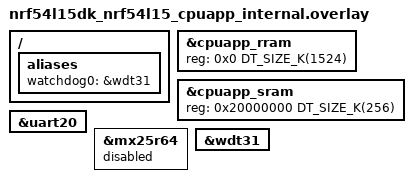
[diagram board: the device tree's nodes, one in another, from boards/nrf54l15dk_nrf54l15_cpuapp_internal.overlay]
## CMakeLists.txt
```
#
# Copyright (c) 2021 Nordic Semiconductor ASA
#
# SPDX-License-Identifier: LicenseRef-Nordic-5-Clause
#

cmake_minimum_required(VERSION 3.20.0)

find_package(Zephyr HINTS $ENV{ZEPHYR_BASE})

project(dummy)

# Enable GNU STD support and initialize the Matter Data Model.
include(${ZEPHYR_CONNECTEDHOMEIP_MODULE_DIR}/config/nrfconnect/app/enable-gnu-std.cmake)

# NORDIC SDK APP START
target_sources(app PRIVATE
    src/main.c
)

# NORDIC SDK APP END
```

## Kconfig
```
#
# Copyright (c) 2022 Nordic Semiconductor
#
# SPDX-License-Identifier: LicenseRef-Nordic-5-Clause
#
mainmenu "Matter dummy sample for DFU integration purpose"

config CHIP_DEVICE_VENDOR_ID
	int
	default 65521

config CHIP_DEVICE_PRODUCT_ID
	int
	default 32768

config UPDATEABLE_IMAGE_NUMBER
    int
    default 1

source "${ZEPHYR_CONNECTEDHOMEIP_MODULE_DIR}/config/nrfconnect/chip-module/Kconfig.features"
source "${ZEPHYR_CONNECTEDHOMEIP_MODULE_DIR}/config/nrfconnect/chip-module/Kconfig.defaults"
source "Kconfig.zephyr"
```

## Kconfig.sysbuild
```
#
# Copyright (c) 2023 Nordic Semiconductor ASA
#
# SPDX-License-Identifier: LicenseRef-Nordic-5-Clause
#

# Choose empty network core
config NRF_DEFAULT_EMPTY
	default y

#### Bootloader
choice BOOTLOADER
	default BOOTLOADER_MCUBOOT if !BOARD_NRF21540DK
endchoice

if BOOTLOADER_MCUBOOT

#### DFU multi-image support
config DFU_MULTI_IMAGE_PACKAGE_BUILD
	default y

config DFU_MULTI_IMAGE_PACKAGE_APP
	default y

config PM_EXTERNAL_FLASH_MCUBOOT_SECONDARY
	default y

#### DFU network core configuration
if SOC_SERIES_NRF53X

config MCUBOOT_UPDATEABLE_IMAGES
	default 2

choice MCUBOOT_MODE
	default MCUBOOT_MODE_OVERWRITE_ONLY
endchoice

choice BOOT_SIGNATURE_TYPE
	default BOOT_SIGNATURE_TYPE_RSA
endchoice

config SECURE_BOOT_NETCORE
	default y

config NETCORE_APP_UPDATE
	default y

config DFU_MULTI_IMAGE_PACKAGE_NET
	default y

endif # SOC_SERIES_NRF53X

if BOARD_NRF54L15DK || BOARD_NRF54LM20DK

# Disable checking the external drivers for nRF54L15 and nRF54LM20 DKs.
config PM_OVERRIDE_EXTERNAL_DRIVER_CHECK
	default y

endif # BOARD_NRF54L15DK || BOARD_NRF54LM20DK

endif # BOOTLOADER_MCUBOOT

config MATTER_OTA
	default y

config MATTER_OTA_IMAGE_FILE_NAME
	string
	default "matter.ota"

# Store the Wi-Fi firmware patch on external flash by default
if WIFI_NRF70

choice WIFI_PATCHES_EXT_FLASH_SUPPORT
	default WIFI_PATCHES_EXT_FLASH_STORE

endchoice

config DFU_MULTI_IMAGE_PACKAGE_WIFI_FW_PATCH
	default y

endif # WIFI_NRF70

source "${ZEPHYR_BASE}/share/sysbuild/Kconfig"
```

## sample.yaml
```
sample:
  description: Matter Dummy Sample
  name: Matter Dummy
tests:
  sample.matter.dummy:
    sysbuild: true
    build_only: true
    integration_platforms:
      - nrf52840dk/nrf52840
      - nrf5340dk/nrf5340/cpuapp
      - nrf7002dk/nrf5340/cpuapp
      - nrf54l15dk/nrf54l15/cpuapp
      - nrf54l15dk/nrf54l15/cpuapp/ns
      - nrf54lm20dk/nrf54lm20a/cpuapp
    platform_allow:
      - nrf52840dk/nrf52840
      - nrf5340dk/nrf5340/cpuapp
      - nrf7002dk/nrf5340/cpuapp
      - nrf54l15dk/nrf54l15/cpuapp
      - nrf54l15dk/nrf54l15/cpuapp/ns
      - nrf54lm20dk/nrf54lm20a/cpuapp
    tags: sysbuild ci_samples_matter
  sample.matter.dummy.internal:
    sysbuild: true
    build_only: true
    integration_platforms:
      - nrf54l15dk/nrf54l15/cpuapp
      - nrf54lm20dk/nrf54lm20a/cpuapp
    platform_allow:
      - nrf54l15dk/nrf54l15/cpuapp
      - nrf54lm20dk/nrf54lm20a/cpuapp
    extra_args:
      - FILE_SUFFIX=internal
    tags: sysbuild ci_samples_matter
```

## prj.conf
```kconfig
#
# Copyright (c) 2022 Nordic Semiconductor ASA
#
# SPDX-License-Identifier: LicenseRef-Nordic-5-Clause
#

CONFIG_PRINTK=y

CONFIG_BOOTLOADER_MCUBOOT=y
CONFIG_IMG_MANAGER=y
CONFIG_STREAM_FLASH=y
CONFIG_STREAM_FLASH_ERASE=y
CONFIG_FLASH=y
CONFIG_FLASH_MAP=y
CONFIG_MCUBOOT_IMG_MANAGER=y
CONFIG_NEWLIB_LIBC=y
```

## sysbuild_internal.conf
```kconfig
#
# Copyright (c) 2024 Nordic Semiconductor
#
# SPDX-License-Identifier: LicenseRef-Nordic-5-Clause
#

SB_CONFIG_PM_OVERRIDE_EXTERNAL_DRIVER_CHECK=n
SB_CONFIG_PM_EXTERNAL_FLASH_MCUBOOT_SECONDARY=n

# Enable the DFU image compression.
SB_CONFIG_MCUBOOT_MODE_OVERWRITE_ONLY=y
SB_CONFIG_MCUBOOT_COMPRESSED_IMAGE_SUPPORT=y
```

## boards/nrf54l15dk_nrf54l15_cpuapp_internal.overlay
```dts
/*
 * Copyright (c) 2024 Nordic Semiconductor ASA
 *
 * SPDX-License-Identifier: LicenseRef-Nordic-5-Clause
 */

/ {
	aliases {
		/* Use watchdog wdt31 as the application watchdog */
		watchdog0 = &wdt31;
	};
};

/* restore full RRAM and SRAM space - by default some parts are dedicated to FLRP */
&cpuapp_rram {
	reg = <0x0 DT_SIZE_K(1524)>;
};

&cpuapp_sram {
	reg = <0x20000000 DT_SIZE_K(256)>;
	ranges = <0x0 0x20000000 0x40000>;
};

/* TODO: re-enable HWFC once it's fixed */
&uart20 {
	/delete-property/ hw-flow-control;
};

&mx25r64 {
	status = "disabled";
};

&wdt31 {
	status = "okay";
};
```

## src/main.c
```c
/*
 * Copyright (c) 2021 Nordic Semiconductor ASA
 *
 * SPDX-License-Identifier: LicenseRef-Nordic-5-Clause
 */

#include <zephyr/kernel.h>
#include <zephyr/sys/printk.h>

#ifndef CONFIG_SOC_SERIES_NRF54HX
#include <zephyr/dfu/mcuboot.h>
#endif

int main(void)
{
	printk("Hello world from %s\n", CONFIG_BOARD);

#ifndef CONFIG_SOC_SERIES_NRF54HX
	if (mcuboot_swap_type() == BOOT_SWAP_TYPE_REVERT) {
		if (boot_write_img_confirmed()) {
			printk("Failed to confirm firmware image, it will be reverted on the next boot\n");
		} else {
			printk("New firmware image confirmed\n");
		}
	}
#endif
	return 0;
}
```
